# PAC52XX register map
Vendor: Active-Semi; Series: PAC52XX; File version: 1.0
CPU: CM0 r0p0, little endian, no MPU, no FPU, vendor SysTick, 2 interrupt priority bits
Registers are 32-bit, read-write, reset 0x0 unless marked. A register's access mark holds for its fields unless they carry their own. Offsets are from the block's base; [hi:lo] are bit positions; {n}, {i} and the like mark numbered series; 'fields as' and 'values as' point back to an identical list.

## TIMERA — Timer A Peripheral
Base 0x400D0000
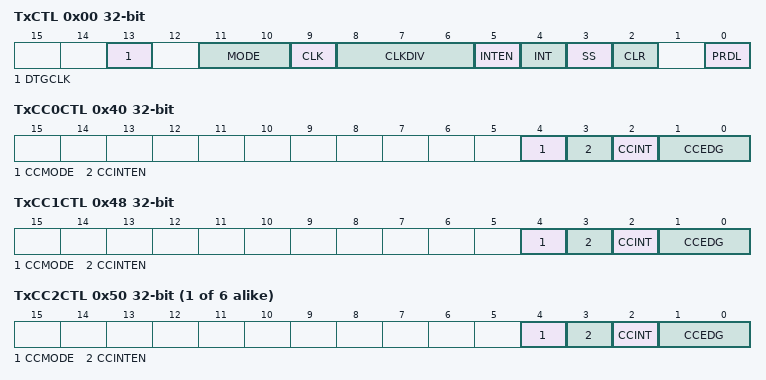
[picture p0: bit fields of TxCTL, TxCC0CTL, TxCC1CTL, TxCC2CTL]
0x00 TxCTL — Timer Control Register
  [13] DTGCLK — DTG clock select
    0=CLK (DTG uses clock selected by TxTCL.CLK); 1=CLKDIV (DTG uses clock selected by TxCTL.CLKDIV)
  [11:10] MODE — timer mode
    0=disabled (timer disabled); 1=up (up mode); 2=up/down mode
  [9] CLK — timer clock input source
    0=HCLK; 1=ACLK
  [8:6] CLKDIV — timer clock divider
    0=/1 (divide by 1); 1=/2 (divide by 2); 2=/4 (divide by 4); 3=/8 (divide by 8); 4=/16 (divide by 16); 5=/32 (divide by 32); 6=/64 (divide by 64); 7=/128 (divide by 128)
  [5] INTEN — Timer interrupt enable
    0=enabled (timer interrupt enabled); 1=disabled (timer interrupt disabled)
  [4] INT — Timer interrupt
    0=interrupt flag, write 1 to clear; 1=No interrupt
  [3] SS — Timer single shot
    0=Continuous mode; 1=Single shot mode
  [2] CLR — Timer clear
    0=Clear Timer, hold in reset, set SYNC_OUT; 1=noclear (Do not clear timer, clear SYNC_OUT)
  [0] PRDL — Timer Period Latch
    0=period (Latch timer values counting up at TxPRD-1); 1=wrap (Latch timer values when counting down to 1)
0x04 TxPRD — timer period
  [15:0] PERIOD — timer period value
0x08 TxCTR ro — timer counter
  [15:0] CTR — timer counter value
0x40 TxCC0CTL — timer capture and compare control unit 0
  [4] CCMODE — capture and compare mode
    0=compare mode; 1=capture mode
  [3] CCINTEN — capture and compare interrupt enable
    0=disabled (interrupt disabled); 1=enabled (interrupt enabled)
  [2] CCINT — capture and compare interrupt
    0=none (no interrupt detected); 1=interrupt, write 1b to clear
  [1:0] CCEDG — capture mode edge detect
    0=hitolow (high to low transition only); 1=low to high transitions only; 2=both high to low and low to high transitions
{0x44+8i} TxCC{i}CTR (i=0..7) — capture and compare counter unit {i}
  [15:0] CCCTR — capture and compare counter value
0x48 TxCC1CTL — timer capture and compare control unit 0
  fields as TxCC0CTL
{0x40+8i} TxCC{i}CTL (i=2..7) — timer capture and compare control unit {i}
  fields as TxCC0CTL
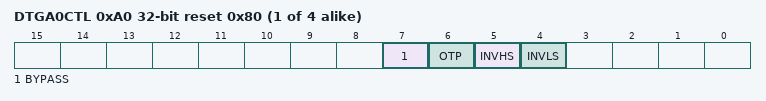
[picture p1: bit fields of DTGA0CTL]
{0xA0+0x10*i} DTGA{i}CTL reset 0x80 (i=0..3) — Timer A dead-time generator control unit {i}
  [7] BYPASS — bypass dead-time generation
    0=disabled (do not bypass dead-time generation); 1=enabled (bypass dead-time generation)
  [6] OTP — On-time preservation
    0=disabled (do not extend on time); 1=enabled (extend on time)
  [5] INVHS — Invert high-side output signal
    0=disabled (do not invert high-side output signal); 1=enabled (invert high-side output signal)
  [4] INVLS — Invert low-side output signal
    0=disabled (do not invert low-side output signal); 1=enabled (invert low-side output signal)
{0xA4+0x10*i} DTGA{i}LED (i=0..3) — Timer A dead-time generator leading-edge delay counter unit {i}
  [11:0] LED — leading-edge delay counter
{0xA8+0x10*i} DTGA{i}TED (i=0..2) — Timer A dead-time generator trailing-edge delay counter unit {i}
  [11:0] TED — trailing-edge delay counter
0xD8 DTGA3TED — Timer A dead-time generator trailing-edge delay counter unit 0
  [11:0] TED — trailing-edge delay counter

## TIMERB — Timer B Peripheral
Base 0x400E0000
Registers as TIMERA, without TxCC{n}CTL (n=4..7), TxCC{n}CTR (n=4..7), DTGA{n}CTL (n=0..3), DTGA{n}LED (n=0..3), DTGA{n}TED (n=0..3); these are added or differ:
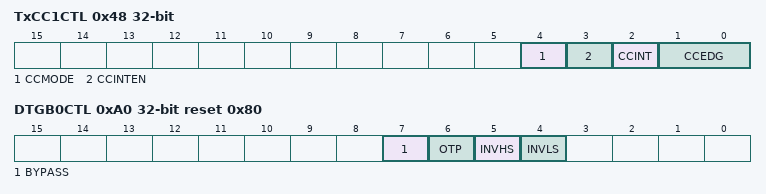
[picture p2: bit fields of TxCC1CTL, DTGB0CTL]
0x48 TxCC1CTL — timer capture and compare control unit 1
  fields as TIMERA.TxCC0CTL
0xA0 DTGB0CTL reset 0x80 — Timer B dead-time generator control unit 0
  fields as TIMERA.DTGA0CTL
0xA4 DTGB0LED — Timer B dead-time generator leading-edge delay counter unit 0
  [11:0] LED — leading-edge delay counter
0xA8 DTGB0TED — Timer B dead-time generator trailing-edge delay counter unit 0
  [11:0] TED — trailing-edge delay counter

## TIMERC — Timer C Peripheral
Base 0x400F0000
Registers as TIMERB, without TxCC2CTL, TxCC2CTR, TxCC3CTL, TxCC3CTR, DTGB0CTL, DTGB0LED, DTGB0TED; these are added or differ:
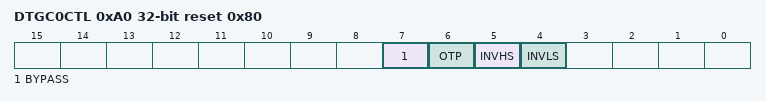
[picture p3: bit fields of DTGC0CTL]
0xA0 DTGC0CTL reset 0x80 — Timer C dead-time generator control unit 0
  fields as TIMERA.DTGA0CTL
0xA4 DTGC0LED — Timer C dead-time generator leading-edge delay counter unit 0
  [11:0] LED — leading-edge delay counter
0xA8 DTGC0TED — Timer C dead-time generator trailing-edge delay counter unit 0
  [11:0] TED — trailing-edge delay counter

## TIMERD — Timer D Peripheral
Base 0x40100000
Registers as TIMERB, without TxCC2CTL, TxCC2CTR, TxCC3CTL, TxCC3CTR, DTGB0CTL, DTGB0LED, DTGB0TED; these are added or differ:
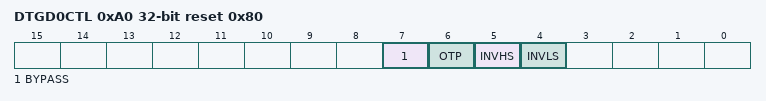
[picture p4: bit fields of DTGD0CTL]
0xA0 DTGD0CTL reset 0x80 — Timer A dead-time generator control unit 0
  fields as TIMERA.DTGA0CTL
0xA4 DTGD0LED — Timer A dead-time generator leading-edge delay counter unit 0
  [11:0] LED — leading-edge delay counter
0xA8 DTGD0TED — Timer A dead-time generator trailing-edge delay counter unit 0
  [11:0] TED — trailing-edge delay counter
